# GAP8 register map
Vendor: GreenWaves Technologies SAS; Series: GAP8; File version: 1.3.1
CPU: other r1p0, little endian, MPU, no FPU, I-cache, DTCM, false interrupt priority bits
Registers are 32-bit, read-write, reset 0x0 unless marked. A register's access mark holds for its fields unless they carry their own. Offsets are from the block's base; [hi:lo] are bit positions; lines under a group give offsets from that group; {n}, {i} and the like mark numbered series; 'fields as' and 'values as' point back to an identical list.

## apb_gpio — GPIO
Base 0x1A101000
0x00 paddir — GPIO pad direction configuration register.
  [31:0] dir — GPIO direction configuration bitfield: - bit[i]=1'b0: Input mode for GPIO[i] - bit[i]=1'b1: Output mode for GPIO[i]
0x04 padin ro — GPIO pad input value register.
  [31:0] data_in — GPIO input data read bitfield. DATA_IN[i] corresponds to input data of GPIO[i].
0x08 padout — GPIO pad output value register.
  [31:0] data_out — GPIO output data read bitfield. DATA_OUT[i] corresponds to output data set on GPIO[i].
0x0C inten — GPIO pad interrupt enable configuration register.
  [31:0] inten — GPIO interrupt enable configuration bitfield: - bit[i]=1'b0: disable interrupt for GPIO[i] - bit[i]=1'b1: enable interrupt for GPIO[i]
0x10 inttype0 — GPIO pad interrupt type bit 0 configuration register.
  [31:0] inttype0 — GPIO[15:0] interrupt type configuration bitfield: - bit[2*i+1:2*i]=2'b00: interrupt on falling edge for GPIO[i] - bit[2*i+1:2*i]=2'b01: interrupt on rising edge for GPIO[i] - bit[2*i+1:2*i]=2'b10: interrupt on rising and falling edge for GPIO[i] - bit[2*i+1:2*i]=2'b11: RFU
0x14 inttype1 — GPIO pad interrupt type bit 1 configuration register.
  [31:0] inttype1 — GPIO[31:16] interrupt type configuration bitfield: - bit[2*i+1:2*i]=2'b00: interrupt on falling edge for GPIO[16+i] - bit[2*i+1:2*i]=2'b01: interrupt on rising edge for GPIO[16+i] - bit[2*i+1:2*i]=2'b10: interrupt on rising and falling edge for GPIO[16+i] - bit[2*i+1:2*i]=2'b11: RFU
0x18 intstatus ro — GPIO pad interrupt status register.
  [31:0] intstatus — GPIO Interrupt status flags bitfield. INTSTATUS[i]=1 when interrupt received on GPIO[i]. INTSTATUS is cleared when it is red. GPIO interrupt line is also cleared when INTSTATUS register is red.
0x1C gpioen — GPIO pad enable configuration register.
  [31:0] gpioen — GPIO clock enable configuration bitfield: - bit[i]=1'b0: disable clock for GPIO[i] - bit[i]=1'b1: enable clock for GPIO[i] GPIOs are gathered by groups of 4. The clock gating of one group is done only if all 4 GPIOs are disabled. Clock must be enabled for a GPIO if it's direction is configured in input mode.
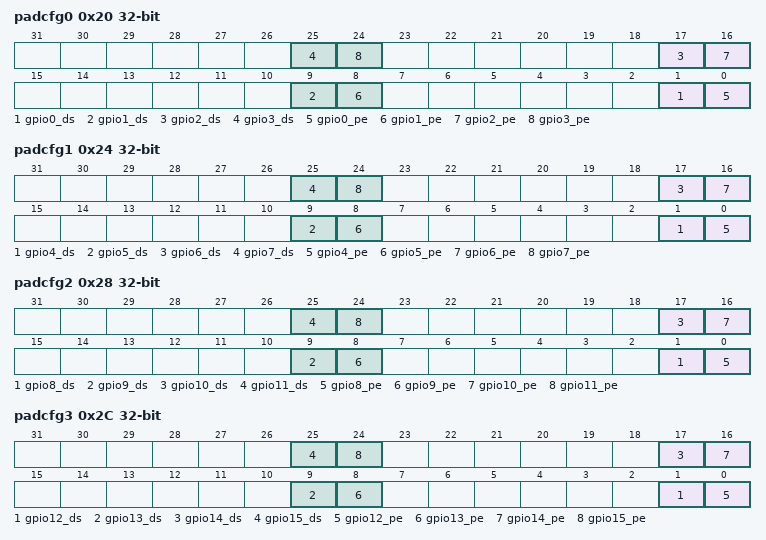
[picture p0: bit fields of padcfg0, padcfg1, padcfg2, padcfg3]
0x20 padcfg0 — GPIO pad pin 0 to 3 configuration register.
  [8n+1] gpio{n}_ds (n=0..3) — GPIO[{n}] drive strength configuration bitfield
    0=low_drive_strength (set to low drive strength); 1=high drive strength
  [8n] gpio{n}_pe (n=0..3) — GPIO[{n}] pull activation configuration bitfield
    0=pull_disabled (set to pull disabled); 1=pull_enabled (set to pull enabled)
0x24 padcfg1 — GPIO pad pin 4 to 7 configuration register.
  [8n-31] gpio{n}_ds (n=4..7) — GPIO[{n}] drive strength configuration bitfield
    values as padcfg0.gpio0_ds
  [8n-32] gpio{n}_pe (n=4..7) — GPIO[{n}] pull activation configuration bitfield
    values as padcfg0.gpio0_pe
0x28 padcfg2 — GPIO pad pin 8 to 11 configuration register.
  [8n-63] gpio{n}_ds (n=8..11) — GPIO[{n}] drive strength configuration bitfield
    values as padcfg0.gpio0_ds
  [8n-64] gpio{n}_pe (n=8..11) — GPIO[{n}] pull activation configuration bitfield
    values as padcfg0.gpio0_pe
0x2C padcfg3 — GPIO pad pin 12 to 15 configuration register.
  [8n-95] gpio{n}_ds (n=12..15) — GPIO[{n}] drive strength configuration bitfield
    values as padcfg0.gpio0_ds
  [8n-96] gpio{n}_pe (n=12..15) — GPIO[{n}] pull activation configuration bitfield
    values as padcfg0.gpio0_pe
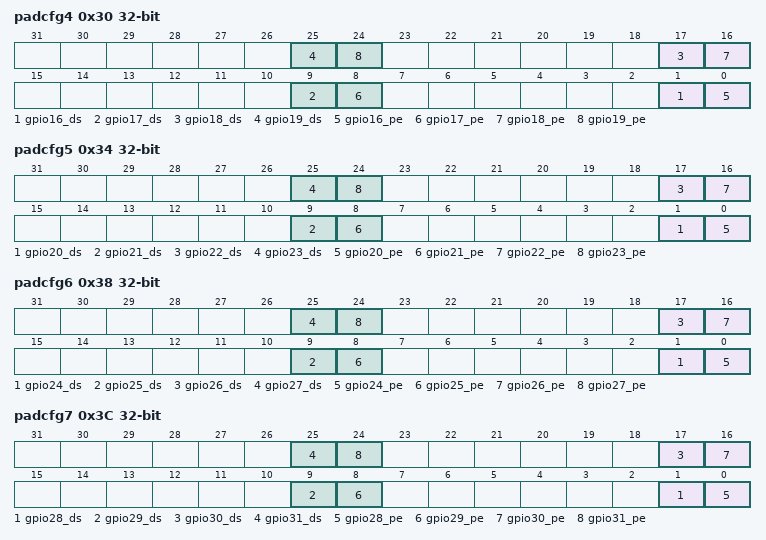
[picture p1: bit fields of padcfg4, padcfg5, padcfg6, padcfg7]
0x30 padcfg4 — GPIO pad pin 16 to 19 configuration register.
  [8n-127] gpio{n}_ds (n=16..19) — GPIO[{n}] drive strength configuration bitfield
    values as padcfg0.gpio0_ds
  [8n-128] gpio{n}_pe (n=16..19) — GPIO[{n}] pull activation configuration bitfield
    values as padcfg0.gpio0_pe
0x34 padcfg5 — GPIO pad pin 20 to 23 configuration register.
  [8n-159] gpio{n}_ds (n=20..23) — GPIO[{n}] drive strength configuration bitfield
    values as padcfg0.gpio0_ds
  [8n-160] gpio{n}_pe (n=20..23) — GPIO[{n}] pull activation configuration bitfield
    values as padcfg0.gpio0_pe
0x38 padcfg6 — GPIO pad pin 24 to 27 configuration register.
  [8n-191] gpio{n}_ds (n=24..27) — GPIO[{n}] drive strength configuration bitfield
    values as padcfg0.gpio0_ds
  [8n-192] gpio{n}_pe (n=24..27) — GPIO[{n}] pull activation configuration bitfield
    values as padcfg0.gpio0_pe
0x3C padcfg7 — GPIO pad pin 28 to 31 configuration register.
  [8n-223] gpio{n}_ds (n=28..31) — GPIO[{n}] drive strength configuration bitfield
    values as padcfg0.gpio0_ds
  [8n-224] gpio{n}_pe (n=28..31) — GPIO[{n}] pull activation configuration bitfield
    values as padcfg0.gpio0_pe
